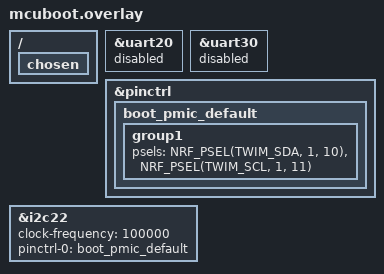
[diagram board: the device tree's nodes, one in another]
#include <zephyr/dt-bindings/pinctrl/nrf-pinctrl.h>

/ {
 chosen {
  /delete-property/ zephyr,console;
  /delete-property/ zephyr,shell-uart;
  /delete-property/ zephyr,uart-mcumgr;
  /delete-property/ zephyr,bt-mon-uart;
  /delete-property/ zephyr,bt-c2h-uart;
 };
};
&uart20 { status = "disabled"; };
&uart30 { status = "disabled"; };

/* Main bus only: the sensor bus and switched rail remain inactive. */
&pinctrl {
 boot_pmic_default: boot_pmic_default {
  group1 { psels = <NRF_PSEL(TWIM_SDA, 1, 10)>, <NRF_PSEL(TWIM_SCL, 1, 11)>; };
 };
};
&i2c22 {
 status = "okay";
 clock-frequency = <100000>;
 pinctrl-0 = <&boot_pmic_default>;
 pinctrl-names = "default";
};
